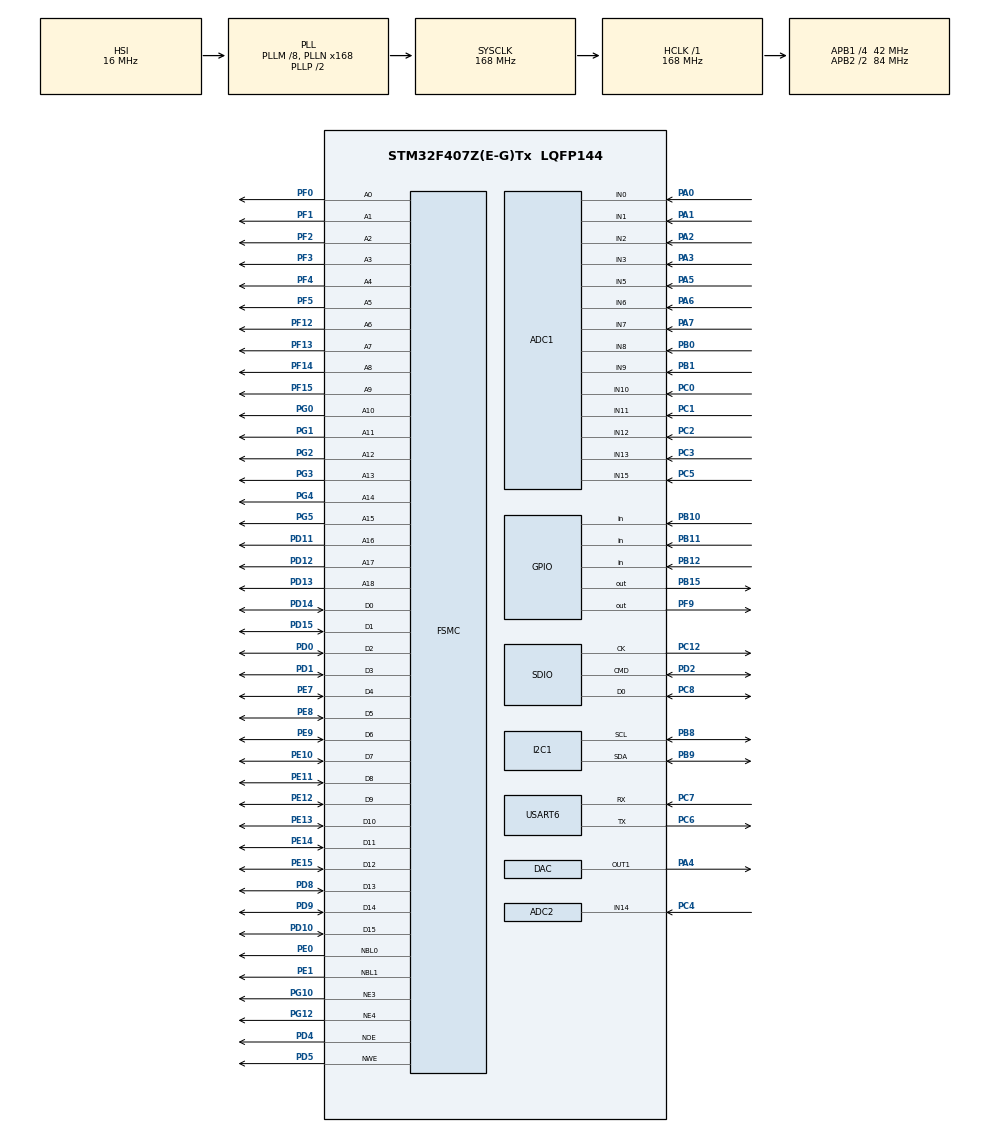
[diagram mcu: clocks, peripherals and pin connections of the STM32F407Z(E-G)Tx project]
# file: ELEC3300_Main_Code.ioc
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ADC1.Channel-0\#ChannelRegularConversion=ADC_CHANNEL_0
ADC1.Channel-1\#ChannelRegularConversion=ADC_CHANNEL_1
ADC1.Channel-10\#ChannelRegularConversion=ADC_CHANNEL_11
ADC1.Channel-11\#ChannelRegularConversion=ADC_CHANNEL_12
ADC1.Channel-12\#ChannelRegularConversion=ADC_CHANNEL_13
ADC1.Channel-13\#ChannelRegularConversion=ADC_CHANNEL_15
ADC1.Channel-2\#ChannelRegularConversion=ADC_CHANNEL_2
ADC1.Channel-3\#ChannelRegularConversion=ADC_CHANNEL_3
ADC1.Channel-4\#ChannelRegularConversion=ADC_CHANNEL_5
ADC1.Channel-5\#ChannelRegularConversion=ADC_CHANNEL_6
ADC1.Channel-6\#ChannelRegularConversion=ADC_CHANNEL_7
ADC1.Channel-7\#ChannelRegularConversion=ADC_CHANNEL_8
ADC1.Channel-8\#ChannelRegularConversion=ADC_CHANNEL_9
ADC1.Channel-9\#ChannelRegularConversion=ADC_CHANNEL_10
ADC1.ClockPrescaler=ADC_CLOCK_SYNC_PCLK_DIV4
ADC1.ContinuousConvMode=ENABLE
ADC1.DMAContinuousRequests=ENABLE
ADC1.NbrOfConversion=14
ADC1.NbrOfConversionFlag=1
ADC1.Rank-0\#ChannelRegularConversion=1
ADC1.Rank-1\#ChannelRegularConversion=2
ADC1.Rank-10\#ChannelRegularConversion=11
ADC1.Rank-11\#ChannelRegularConversion=12
ADC1.Rank-12\#ChannelRegularConversion=13
ADC1.Rank-13\#ChannelRegularConversion=14
ADC1.Rank-2\#ChannelRegularConversion=3
ADC1.Rank-3\#ChannelRegularConversion=4
ADC1.Rank-4\#ChannelRegularConversion=5
ADC1.Rank-5\#ChannelRegularConversion=6
ADC1.Rank-6\#ChannelRegularConversion=7
ADC1.Rank-7\#ChannelRegularConversion=8
ADC1.Rank-8\#ChannelRegularConversion=9
ADC1.Rank-9\#ChannelRegularConversion=10
ADC1.SamplingTime-0\#ChannelRegularConversion=ADC_SAMPLETIME_56CYCLES
ADC1.SamplingTime-1\#ChannelRegularConversion=ADC_SAMPLETIME_56CYCLES
ADC1.SamplingTime-10\#ChannelRegularConversion=ADC_SAMPLETIME_56CYCLES
ADC1.SamplingTime-11\#ChannelRegularConversion=ADC_SAMPLETIME_56CYCLES
ADC1.SamplingTime-12\#ChannelRegularConversion=ADC_SAMPLETIME_56CYCLES
ADC1.SamplingTime-13\#ChannelRegularConversion=ADC_SAMPLETIME_56CYCLES
ADC1.SamplingTime-2\#ChannelRegularConversion=ADC_SAMPLETIME_56CYCLES
ADC1.SamplingTime-3\#ChannelRegularConversion=ADC_SAMPLETIME_56CYCLES
ADC1.SamplingTime-4\#ChannelRegularConversion=ADC_SAMPLETIME_56CYCLES
ADC1.SamplingTime-5\#ChannelRegularConversion=ADC_SAMPLETIME_56CYCLES
ADC1.SamplingTime-6\#ChannelRegularConversion=ADC_SAMPLETIME_56CYCLES
ADC1.SamplingTime-7\#ChannelRegularConversion=ADC_SAMPLETIME_56CYCLES
ADC1.SamplingTime-8\#ChannelRegularConversion=ADC_SAMPLETIME_56CYCLES
ADC1.SamplingTime-9\#ChannelRegularConversion=ADC_SAMPLETIME_56CYCLES
ADC1.master=1
ADC2.Channel-0\#ChannelRegularConversion=ADC_CHANNEL_14
ADC2.ClockPrescaler=ADC_CLOCK_SYNC_PCLK_DIV4
ADC2.ContinuousConvMode=ENABLE
ADC2.DMAContinuousRequests=ENABLE
ADC2.NbrOfConversionFlag=1
ADC2.Rank-0\#ChannelRegularConversion=1
ADC2.SamplingTime-0\#ChannelRegularConversion=ADC_SAMPLETIME_3CYCLES
DAC.DAC_Trigger=DAC_TRIGGER_T4_TRGO
Dma.ADC1.4.Direction=DMA_PERIPH_TO_MEMORY
Dma.ADC1.4.FIFOMode=DMA_FIFOMODE_DISABLE
Dma.ADC1.4.Instance=DMA2_Stream4
Dma.ADC1.4.MemDataAlignment=DMA_MDATAALIGN_HALFWORD
Dma.ADC1.4.MemInc=DMA_MINC_ENABLE
Dma.ADC1.4.Mode=DMA_CIRCULAR
Dma.ADC1.4.PeriphDataAlignment=DMA_PDATAALIGN_HALFWORD
Dma.ADC1.4.PeriphInc=DMA_PINC_DISABLE
Dma.ADC1.4.Priority=DMA_PRIORITY_LOW
Dma.ADC2.2.Direction=DMA_PERIPH_TO_MEMORY
Dma.ADC2.2.FIFOMode=DMA_FIFOMODE_DISABLE
Dma.ADC2.2.Instance=DMA2_Stream2
Dma.ADC2.2.MemDataAlignment=DMA_MDATAALIGN_HALFWORD
Dma.ADC2.2.MemInc=DMA_MINC_ENABLE
Dma.ADC2.2.Mode=DMA_NORMAL
Dma.ADC2.2.PeriphDataAlignment=DMA_PDATAALIGN_HALFWORD
Dma.ADC2.2.PeriphInc=DMA_PINC_DISABLE
Dma.ADC2.2.Priority=DMA_PRIORITY_LOW
Dma.DAC1.3.Direction=DMA_MEMORY_TO_PERIPH
Dma.DAC1.3.FIFOMode=DMA_FIFOMODE_DISABLE
Dma.DAC1.3.Instance=DMA1_Stream5
Dma.DAC1.3.MemDataAlignment=DMA_MDATAALIGN_HALFWORD
Dma.DAC1.3.MemInc=DMA_MINC_ENABLE
Dma.DAC1.3.Mode=DMA_NORMAL
Dma.DAC1.3.PeriphDataAlignment=DMA_PDATAALIGN_HALFWORD
Dma.DAC1.3.PeriphInc=DMA_PINC_DISABLE
Dma.DAC1.3.Priority=DMA_PRIORITY_VERY_HIGH
Dma.MEMTOMEM.5.Direction=DMA_MEMORY_TO_MEMORY
Dma.MEMTOMEM.5.FIFOMode=DMA_FIFOMODE_ENABLE
Dma.MEMTOMEM.5.FIFOThreshold=DMA_FIFO_THRESHOLD_FULL
Dma.MEMTOMEM.5.Instance=DMA2_Stream1
Dma.MEMTOMEM.5.MemBurst=DMA_MBURST_SINGLE
Dma.MEMTOMEM.5.MemDataAlignment=DMA_MDATAALIGN_HALFWORD
Dma.MEMTOMEM.5.MemInc=DMA_MINC_ENABLE
Dma.MEMTOMEM.5.Mode=DMA_NORMAL
Dma.MEMTOMEM.5.PeriphBurst=DMA_PBURST_SINGLE
Dma.MEMTOMEM.5.PeriphDataAlignment=DMA_PDATAALIGN_HALFWORD
Dma.MEMTOMEM.5.PeriphInc=DMA_PINC_ENABLE
Dma.MEMTOMEM.5.Priority=DMA_PRIORITY_HIGH
Dma.Request0=SDIO_RX
Dma.Request1=SDIO_TX
Dma.Request2=ADC2
Dma.Request3=DAC1
Dma.Request4=ADC1
Dma.Request5=MEMTOMEM
Dma.SDIO_RX.0.Direction=DMA_PERIPH_TO_MEMORY
Dma.SDIO_RX.0.FIFOMode=DMA_FIFOMODE_ENABLE
Dma.SDIO_RX.0.FIFOThreshold=DMA_FIFO_THRESHOLD_FULL
Dma.SDIO_RX.0.Instance=DMA2_Stream6
Dma.SDIO_RX.0.MemBurst=DMA_MBURST_INC4
Dma.SDIO_RX.0.MemDataAlignment=DMA_MDATAALIGN_WORD
Dma.SDIO_RX.0.MemInc=DMA_MINC_ENABLE
Dma.SDIO_RX.0.Mode=DMA_PFCTRL
Dma.SDIO_RX.0.PeriphBurst=DMA_PBURST_INC4
Dma.SDIO_RX.0.PeriphDataAlignment=DMA_PDATAALIGN_WORD
Dma.SDIO_RX.0.PeriphInc=DMA_PINC_DISABLE
Dma.SDIO_RX.0.Priority=DMA_PRIORITY_LOW
Dma.SDIO_TX.1.Direction=DMA_MEMORY_TO_PERIPH
Dma.SDIO_TX.1.FIFOMode=DMA_FIFOMODE_ENABLE
Dma.SDIO_TX.1.FIFOThreshold=DMA_FIFO_THRESHOLD_FULL
Dma.SDIO_TX.1.Instance=DMA2_Stream3
Dma.SDIO_TX.1.MemBurst=DMA_MBURST_INC4
Dma.SDIO_TX.1.MemDataAlignment=DMA_MDATAALIGN_WORD
Dma.SDIO_TX.1.MemInc=DMA_MINC_ENABLE
Dma.SDIO_TX.1.Mode=DMA_PFCTRL
Dma.SDIO_TX.1.PeriphBurst=DMA_PBURST_INC4
Dma.SDIO_TX.1.PeriphDataAlignment=DMA_PDATAALIGN_WORD
Dma.SDIO_TX.1.PeriphInc=DMA_PINC_DISABLE
Dma.SDIO_TX.1.Priority=DMA_PRIORITY_LOW
FATFS._FS_EXFAT=0
FATFS._MAX_SS=4096
FATFS._USE_LFN=1
FSMC.AddressSetupTime1=1
FSMC.AddressSetupTime2=0
FSMC.BusTurnAroundDuration1=0
FSMC.BusTurnAroundDuration2=0
FSMC.DataSetupTime1=5
FSMC.DataSetupTime2=8
FSMC.WriteOperation2=FSMC_WRITE_OPERATION_ENABLE
I2C1.I2C_Mode=I2C_Fast
Mcu.Family=STM32F4
Mcu.Name=STM32F407Z(E-G)Tx
Mcu.Package=LQFP144
NVIC.ADC_IRQn=true\:0\:0\:false\:false\:true\:true\:true\:true
NVIC.DMA1_Stream5_IRQn=true\:0\:0\:false\:false\:true\:false\:true\:true
NVIC.DMA2_Stream2_IRQn=true\:0\:0\:false\:false\:true\:false\:true\:true
NVIC.DMA2_Stream3_IRQn=true\:0\:0\:false\:false\:true\:false\:true\:true
NVIC.DMA2_Stream4_IRQn=true\:0\:0\:false\:false\:true\:false\:true\:true
NVIC.DMA2_Stream6_IRQn=true\:0\:0\:false\:false\:true\:false\:true\:true
NVIC.PriorityGroup=NVIC_PRIORITYGROUP_4
PA0-WKUP.Signal=ADCx_IN0
PA1.Signal=ADCx_IN1
PA13.Mode=JTAG_4_pins
PA13.Signal=SYS_JTMS-SWDIO
PA14.Mode=JTAG_4_pins
PA14.Signal=SYS_JTCK-SWCLK
PA15.Mode=JTAG_4_pins
PA15.Signal=SYS_JTDI
PA2.Signal=ADCx_IN2
PA3.Signal=ADCx_IN3
PA4.Signal=COMP_DAC1_group
PA5.Signal=ADCx_IN5
PA6.Signal=ADCx_IN6
PA7.Signal=ADCx_IN7
PB0.Signal=ADCx_IN8
PB1.Signal=ADCx_IN9
PB10.GPIO_PuPd=GPIO_PULLDOWN
PB10.Signal=GPIO_Input
PB11.GPIO_PuPd=GPIO_PULLDOWN
PB11.Signal=GPIO_Input
PB12.Signal=GPIO_Input
PB15.Signal=GPIO_Output
PB3.Mode=JTAG_4_pins
PB3.Signal=SYS_JTDO-SWO
PB8.Mode=I2C
PB8.Signal=I2C1_SCL
PB9.Mode=I2C
PB9.Signal=I2C1_SDA
PC0.Signal=ADCx_IN10
PC1.Signal=ADCx_IN11
PC12.Mode=SD_1_bit
PC12.Signal=SDIO_CK
PC2.Signal=ADCx_IN12
PC3.Signal=ADCx_IN13
PC4.Signal=ADCx_IN14
PC5.Signal=ADCx_IN15
PC6.Mode=Asynchronous
PC6.Signal=USART6_TX
PC7.Mode=Asynchronous
PC7.Signal=USART6_RX
PC8.Mode=SD_1_bit
PC8.Signal=SDIO_D0
PD0.Signal=FSMC_D2_DA2
PD1.Signal=FSMC_D3_DA3
PD10.Signal=FSMC_D15_DA15
PD11.Signal=FSMC_A16_CLE
PD12.Signal=FSMC_A17_ALE
PD13.Signal=FSMC_A18
PD14.Signal=FSMC_D0_DA0
PD15.Signal=FSMC_D1_DA1
PD2.Mode=SD_1_bit
PD2.Signal=SDIO_CMD
PD4.Signal=FSMC_NOE
PD5.Signal=FSMC_NWE
PD8.Signal=FSMC_D13_DA13
PD9.Signal=FSMC_D14_DA14
PE0.Signal=FSMC_NBL0
PE1.Signal=FSMC_NBL1
PE10.Signal=FSMC_D7_DA7
PE11.Signal=FSMC_D8_DA8
PE12.Signal=FSMC_D9_DA9
PE13.Signal=FSMC_D10_DA10
PE14.Signal=FSMC_D11_DA11
PE15.Signal=FSMC_D12_DA12
PE7.Signal=FSMC_D4_DA4
PE8.Signal=FSMC_D5_DA5
PE9.Signal=FSMC_D6_DA6
PF0.Signal=FSMC_A0
PF1.Signal=FSMC_A1
PF12.Signal=FSMC_A6
PF13.Signal=FSMC_A7
PF14.Signal=FSMC_A8
PF15.Signal=FSMC_A9
PF2.Signal=FSMC_A2
PF3.Signal=FSMC_A3
PF4.Signal=FSMC_A4
PF5.Signal=FSMC_A5
PF9.Signal=GPIO_Output
PG0.Signal=FSMC_A10
PG1.Signal=FSMC_A11
PG10.Mode=NorPsramChipSelect3_2
PG10.Signal=FSMC_NE3
PG12.Mode=NorPsramChipSelect4_1
PG12.Signal=FSMC_NE4
PG2.Signal=FSMC_A12
PG3.Signal=FSMC_A13
PG4.Signal=FSMC_A14
PG5.Signal=FSMC_A15
PH0-OSC_IN.Mode=HSE-External-Oscillator
PH0-OSC_IN.Signal=RCC_OSC_IN
PH1-OSC_OUT.Mode=HSE-External-Oscillator
PH1-OSC_OUT.Signal=RCC_OSC_OUT
ProjectManager.HeapSize=0x200
ProjectManager.StackSize=0x400
ProjectManager.TargetToolchain=STM32CubeIDE
RCC.48MHZClocksFreq_Value=48000000
RCC.AHBFreq_Value=168000000
RCC.APB1CLKDivider=RCC_HCLK_DIV4
RCC.APB1Freq_Value=42000000
RCC.APB1TimFreq_Value=84000000
RCC.APB2CLKDivider=RCC_HCLK_DIV2
RCC.APB2Freq_Value=84000000
RCC.APB2TimFreq_Value=168000000
RCC.CortexFreq_Value=168000000
RCC.HCLKFreq_Value=168000000
RCC.HSE_VALUE=8000000
RCC.HSI_VALUE=16000000
RCC.LSE_VALUE=32768
RCC.PLLM=8
RCC.PLLN=168
RCC.PLLQ=7
RCC.SYSCLKFreq_VALUE=168000000
RCC.SYSCLKSource=RCC_SYSCLKSOURCE_PLLCLK
RCC.VCOOutputFreq_Value=336000000
RTC.Date=5
RTC.Hours=12
RTC.Minutes=40
RTC.Month=RTC_MONTH_APRIL
RTC.WeekDay=RTC_WEEKDAY_SUNDAY
RTC.Year=25
SDIO.ClockDiv=12
SH.ADCx_IN0.0=ADC1_IN0,IN0
SH.ADCx_IN1.0=ADC1_IN1,IN1
SH.ADCx_IN10.0=ADC1_IN10,IN10
SH.ADCx_IN11.0=ADC1_IN11,IN11
SH.ADCx_IN12.0=ADC1_IN12,IN12
SH.ADCx_IN13.0=ADC1_IN13,IN13
SH.ADCx_IN14.0=ADC2_IN14,IN14
SH.ADCx_IN15.0=ADC1_IN15,IN15
SH.ADCx_IN2.0=ADC1_IN2,IN2
SH.ADCx_IN3.0=ADC1_IN3,IN3
SH.ADCx_IN5.0=ADC1_IN5,IN5
SH.ADCx_IN6.0=ADC1_IN6,IN6
SH.ADCx_IN7.0=ADC1_IN7,IN7
SH.ADCx_IN8.0=ADC1_IN8,IN8
SH.ADCx_IN9.0=ADC1_IN9,IN9
SH.COMP_DAC1_group.0=DAC_OUT1,DAC_OUT1
SH.FSMC_A0.0=FSMC_A0,19b-a2
SH.FSMC_A1.0=FSMC_A1,19b-a2
SH.FSMC_A10.0=FSMC_A10,19b-a2
SH.FSMC_A11.0=FSMC_A11,19b-a2
SH.FSMC_A12.0=FSMC_A12,19b-a2
SH.FSMC_A13.0=FSMC_A13,19b-a2
SH.FSMC_A14.0=FSMC_A14,19b-a2
SH.FSMC_A15.0=FSMC_A15,19b-a2
SH.FSMC_A16_CLE.0=FSMC_A16,19b-a2
SH.FSMC_A17_ALE.0=FSMC_A17,19b-a2
SH.FSMC_A18.0=FSMC_A18,19b-a2
SH.FSMC_A2.0=FSMC_A2,19b-a2
SH.FSMC_A3.0=FSMC_A3,19b-a2
SH.FSMC_A4.0=FSMC_A4,19b-a2
SH.FSMC_A5.0=FSMC_A5,19b-a2
SH.FSMC_A6.0=FSMC_A6,A6_1
SH.FSMC_A6.1=FSMC_A6,19b-a2
SH.FSMC_A7.0=FSMC_A7,19b-a2
SH.FSMC_A8.0=FSMC_A8,19b-a2
SH.FSMC_A9.0=FSMC_A9,19b-a2
SH.FSMC_D0_DA0.0=FSMC_D0,16b-d1
SH.FSMC_D0_DA0.1=FSMC_D0,16b-d2
SH.FSMC_D10_DA10.0=FSMC_D10,16b-d1
SH.FSMC_D10_DA10.1=FSMC_D10,16b-d2
SH.FSMC_D11_DA11.0=FSMC_D11,16b-d1
SH.FSMC_D11_DA11.1=FSMC_D11,16b-d2
SH.FSMC_D12_DA12.0=FSMC_D12,16b-d1
SH.FSMC_D12_DA12.1=FSMC_D12,16b-d2
SH.FSMC_D13_DA13.0=FSMC_D13,16b-d1
SH.FSMC_D13_DA13.1=FSMC_D13,16b-d2
SH.FSMC_D14_DA14.0=FSMC_D14,16b-d1
SH.FSMC_D14_DA14.1=FSMC_D14,16b-d2
SH.FSMC_D15_DA15.0=FSMC_D15,16b-d1
SH.FSMC_D15_DA15.1=FSMC_D15,16b-d2
SH.FSMC_D1_DA1.0=FSMC_D1,16b-d1
SH.FSMC_D1_DA1.1=FSMC_D1,16b-d2
SH.FSMC_D2_DA2.0=FSMC_D2,16b-d1
SH.FSMC_D2_DA2.1=FSMC_D2,16b-d2
SH.FSMC_D3_DA3.0=FSMC_D3,16b-d1
SH.FSMC_D3_DA3.1=FSMC_D3,16b-d2
SH.FSMC_D4_DA4.0=FSMC_D4,16b-d1
SH.FSMC_D4_DA4.1=FSMC_D4,16b-d2
SH.FSMC_D5_DA5.0=FSMC_D5,16b-d1
SH.FSMC_D5_DA5.1=FSMC_D5,16b-d2
SH.FSMC_D6_DA6.0=FSMC_D6,16b-d1
SH.FSMC_D6_DA6.1=FSMC_D6,16b-d2
SH.FSMC_D7_DA7.0=FSMC_D7,16b-d1
SH.FSMC_D7_DA7.1=FSMC_D7,16b-d2
SH.FSMC_D8_DA8.0=FSMC_D8,16b-d1
SH.FSMC_D8_DA8.1=FSMC_D8,16b-d2
SH.FSMC_D9_DA9.0=FSMC_D9,16b-d1
SH.FSMC_D9_DA9.1=FSMC_D9,16b-d2
SH.FSMC_NBL0.0=FSMC_NBL0,2ByteEnable2
SH.FSMC_NBL1.0=FSMC_NBL1,2ByteEnable2
SH.FSMC_NOE.0=FSMC_NOE,Lcd1
SH.FSMC_NOE.1=FSMC_NOE,Sram2
SH.FSMC_NWE.0=FSMC_NWE,Lcd1
SH.FSMC_NWE.1=FSMC_NWE,Sram2
TIM4.Period=4
TIM4.Prescaler=1679
TIM4.TIM_MasterOutputTrigger=TIM_TRGO_UPDATE
USART6.VirtualMode=VM_ASYNC
VP_FATFS_VS_SDIO.Mode=SDIO
VP_RTC_VS_RTC_Activate.Mode=RTC_Enabled
VP_RTC_VS_RTC_Calendar.Mode=RTC_Calendar
VP_TIM4_VS_ClockSourceINT.Mode=Internal
board=custom

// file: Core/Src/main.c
/* USER CODE BEGIN Header */
/**
  ******************************************************************************
  * @file           : main.c
  * @brief          : Main program body
  ******************************************************************************
  * @attention
  *
  * Copyright (c) 2025 STMicroelectronics.
  * All rights reserved.
  *
  * This software is licensed under terms that can be found in the LICENSE file
  * in the root directory of this software component.
  * If no LICENSE file comes with this software, it is provided AS-IS.
  *
  ******************************************************************************
  */
/* USER CODE END Header */
#include "main.h"
#include "fatfs.h"

/* USER CODE BEGIN Includes */
//#include "state_controller.h"

#include "soundtracks.h"
#include "bitmaps.h"

#include "SDcard.h"
#include "lcd.h"
#include "VL53L0X.h"
#include "MPU6050.h"

#include "Audio_Player.h"
#include "servo_adc_read.h"
#include "pid.h"
#include "servo_pid_set.h"
#include "inverse_kinematics.h"
#include "interaction_timer.h"
#include "uart_receiver.h"
#include "watchdog_function.h"

#include "movement_controller.h"
#include "face_controller.h"
#include "state_controller.h"

/* USER CODE END Includes */

ADC_HandleTypeDef hadc1;
ADC_HandleTypeDef hadc2;
DMA_HandleTypeDef hdma_adc1;
DMA_HandleTypeDef hdma_adc2;

DAC_HandleTypeDef hdac;
DMA_HandleTypeDef hdma_dac1;

I2C_HandleTypeDef hi2c1;

RTC_HandleTypeDef hrtc;

SD_HandleTypeDef hsd;
DMA_HandleTypeDef hdma_sdio_rx;
DMA_HandleTypeDef hdma_sdio_tx;

TIM_HandleTypeDef htim4;

UART_HandleTypeDef huart6;

DMA_HandleTypeDef hdma_memtomem_dma2_stream1;
SRAM_HandleTypeDef hsram1;
SRAM_HandleTypeDef hsram2;

void SystemClock_Config(void);
static void MX_GPIO_Init(void);
static void MX_DMA_Init(void);
static void MX_FSMC_Init(void);
static void MX_SDIO_SD_Init(void);
static void MX_ADC2_Init(void);
static void MX_ADC1_Init(void);
static void MX_DAC_Init(void);
static void MX_TIM4_Init(void);
static void MX_I2C1_Init(void);
static void MX_RTC_Init(void);
static void MX_USART6_UART_Init(void);

/* USER CODE BEGIN 0 */

// FLAT is 100, 0, 0
float acc_x, acc_y, acc_z;

int distance;
/* USER CODE END 0 */

int main(void)
{
  /* USER CODE BEGIN 1 */
  int sys_tick_c = 0, sys_tick_p_1 = 0, sys_tick_p_100 = 0, sys_tick_p_move = 0;
  int walk_state = 0;

//  double femur_trajectory_walk[] = {55, 55, 90, 44};
//  double tibia_trajectory_walk[] = {118, 137, 137, 99};
  double femur_trajectory_walk[4] = {60, 45, 102, 51};
  double tibia_trajectory_walk[4] = {115, 128, 135, 106};

//  double LB_FEMUR_setpoints[bufLen] = {0};
//  double LB_TIBIA_setpoints[bufLen] = {0};
  /* USER CODE END 1 */

  /* MCU Configuration--------------------------------------------------------*/

  /* Reset of all peripherals, Initializes the Flash interface and the Systick. */
  HAL_Init();

  /* Configure the system clock */
  SystemClock_Config();

  /* Initialize all configured peripherals */
  MX_GPIO_Init();
  MX_DMA_Init();
  MX_FSMC_Init();
  MX_SDIO_SD_Init();
  MX_FATFS_Init();
  MX_ADC2_Init();
  MX_ADC1_Init();
  MX_DAC_Init();
  MX_TIM4_Init();
  MX_I2C1_Init();
  MX_RTC_Init();
  MX_USART6_UART_Init();
  /* USER CODE BEGIN 2 */

	// Configuring systick
	HAL_SetTickFreq(HAL_TICK_FREQ_1KHZ);

	// Initalizing the LCD
	LCD_INIT();
	LCD_BackLed_Control(DISABLE);

	// Mounting SD cards
	LCD_DrawString(0, 0, "INIT SD");
	SDcard_STATUS status = SD_Init();
	if (status != SDcard_OK) {
	  HardFault_Handler();
	}
	LCD_DrawString(150, 0, "SD OK");

	// Initializing the MPU6050
	MPU6050_init();
	MPU6050_Read_Accel(&acc_x, &acc_y, &acc_z);

//	 Initalizing the VL53L0X
	statInfo_t_VL53L0X distanceStr;
	initVL53L0X(1, &hi2c1);

	// Configure the sensor for high accuracy and speed in 20 cm.
	setSignalRateLimit(2);
	setVcselPulsePeriod(VcselPeriodPreRange, 10);
	setVcselPulsePeriod(VcselPeriodFinalRange, 14);
	setMeasurementTimingBudget(300 * 1000UL);

	// Initializing the servo angle reading
	servoAngleReader servo_reader;
	servo_reader.servoADC = &hadc1;
	servoReaderStart(&servo_reader);

	// Initalizing the servo pid
	servo_set servoSet;

	// Check out these retarded declarations
	PID_TypeDef LB_Tibia_PID;
	PID_TypeDef LB_Femur_PID;
	PID_TypeDef LB_Shoul_PID;
	PID_TypeDef LF_Tibia_PID;
	PID_TypeDef LF_Femur_PID;
	PID_TypeDef LF_Shoul_PID;
	PID_TypeDef RF_Tibia_PID;
	PID_TypeDef RF_Femur_PID;
	PID_TypeDef RF_Shoul_PID;
	PID_TypeDef RB_Tibia_PID;
	PID_TypeDef RB_Femur_PID;
	PID_TypeDef RB_Shoul_PID;

	// Instantiating the PCA PWM controllers
	static pca9685_handle_t GPWM_1;
	static pca9685_handle_t GPWM_2;

	GPWM_1.device_address = 0x61 << 1;
	GPWM_2.device_address = 0x60 << 1;

	GPWM_1.i2c_handle = &hi2c1;
	GPWM_2.i2c_handle = &hi2c1;

	GPWM_1.inverted = 0;
	GPWM_2.inverted = 0;

	servoSet.pwm_out_1 = &GPWM_1;
	servoSet.pwm_out_2 = &GPWM_2;

	servoSet.LB_Tibia_PID = &LB_Tibia_PID;
	servoSet.LB_Femur_PID = &LB_Femur_PID;
	servoSet.LB_Shoul_PID = &LB_Shoul_PID;
	servoSet.LF_Tibia_PID = &LF_Tibia_PID;
	servoSet.LF_Femur_PID = &LF_Femur_PID;
	servoSet.LF_Shoul_PID = &LF_Shoul_PID;
	servoSet.RF_Tibia_PID = &RF_Tibia_PID;
	servoSet.RF_Femur_PID = &RF_Femur_PID;
	servoSet.RF_Shoul_PID = &RF_Shoul_PID;
	servoSet.RB_Tibia_PID = &RB_Tibia_PID;
	servoSet.RB_Femur_PID = &RB_Femur_PID;
	servoSet.RB_Shoul_PID = &RB_Shoul_PID;

	// Initalizing the PCA9685
	LCD_DrawString(0, 20, "INIT PCA9685");
	if (!pidInit(&servoSet)) {
		LCD_DrawString(150, 20, "FAIL");
		HardFault_Handler();
	}
	LCD_DrawString(150, 20, "PCA9685 OK");

	// Initalizing the inverse kinematic objects
	leg_position LB_pos;
	leg_position RB_pos;
	leg_position LF_pos;
	leg_position RF_pos;

	LB_pos.leg = LB;
	RB_pos.leg = RB;
	LF_pos.leg = LF;
	RF_pos.leg = RF;

	// Initializing the audio player
	audioController AudioCtrl;

	AudioCtrl.hdac = &hdac;
	AudioCtrl.htim = &htim4;
	AudioCtrl.dac_channel = DAC_CHANNEL_1;

	LCD_DrawString(0, 40, "LOADING AUDIO FILE");
	initAudio(&AudioCtrl);
	loadAudioFiles();

	// Initalizing the interaction timer
	interaction_timer interactionTimer;
	interactionTimer.hrtc = &hrtc;
	interactionTimer.sadThresholdDay = SAD_THRESHOLD_DAY;
	interactionTimer.sadThresholdHour = SAD_THRESHOLD_HOUR;
	interactionTimer.sadThresholdMin = SAD_THRESHOLD_MIN;
	interactUpdate(&interactionTimer);

	// Initializing the face controller
	face_controller faceController;
	faceController.animation_counter = 0;

  movement_controller moveController;
  moveController.movement_counter = 0;
  moveController.executing_state = STANDING;

	// Initializing the state controller
	state_controller stateController;
	stateController._servo_reader = &servo_reader;
	stateController.interactionTimer = &interactionTimer;
	stateController._audio_controller = &AudioCtrl;
	stateController.current_mm_state = NORMAL;
	stateController.current_move_state = STANDING;
	stateController.bt_uart = &huart6;
	stateController.distanceStr = &distanceStr;
  /* USER CODE END 2 */

  /* Infinite loop */
  while (1)
  {

    /* USER CODE BEGIN 3 */
	  sys_tick_c = HAL_GetTick();

//	  MPU6050_Read_Accel(&acc_x, &acc_y, &acc_z);
//	  distance = readRangeSingleMillimeters(&distanceStr);

	  // 1 Hz Processes
	  if ((sys_tick_c - sys_tick_p_1) >= 1000) {
		  sys_tick_p_1 = sys_tick_c;
		  HAL_GPIO_TogglePin(GPIOF, GPIO_PIN_9);
		  HAL_StatusTypeDef remote_status = receive_normal_data(stateController.bt_uart, &stateController.joystick_x, &stateController.joystick_y, &stateController.joystick_button, &stateController.ts_button);
		  updateFace(&faceController, &stateController);
	  }

    //  Hz Processes
	  if ((sys_tick_c - sys_tick_p_move) >= 10) {
		  sys_tick_p_move = sys_tick_c;
		  updateMovements(&moveController, &stateController, &servoSet, &LB_pos, &RB_pos, &LF_pos, &RF_pos);
	  }

	  // 1000 Hz Processes
	  if ((sys_tick_c - sys_tick_p_100) >= 1) {
		  sys_tick_p_100 = sys_tick_c;

//		  setDesiredPosition(&LB_pos, X_OFFSET, Y_OFFSET, 3.9);
//		  setDesiredPosition(&RB_pos, X_OFFSET, Y_OFFSET, 3.9);
//		  setDesiredPosition(&LF_pos, X_OFFSET, Y_OFFSET, 3.9);
//		  setDesiredPosition(&RF_pos, X_OFFSET, Y_OFFSET, 3.9);
//
//		  updateLeg(&LB_pos, &servoSet);
//		  updateLeg(&RB_pos, &servoSet);
//		  updateLeg(&LF_pos, &servoSet);
//		  updateLeg(&RF_pos, &servoSet);

		  // Begin the process
		  determineMultimediaState(&stateController);
	      determineMovementState(&stateController);

	      updateLeg(&LB_pos, &servoSet);
		  updateLeg(&RB_pos, &servoSet);
	      updateLeg(&LF_pos, &servoSet);
	      updateLeg(&RF_pos, &servoSet);
	  }

	updateAngles(&servo_reader);
	updateAnglesArray(&servoSet, servo_reader.servoAngles);
	updateServo(&servoSet); // Poll every time!

  }
  /* USER CODE END 3 */
}

void SystemClock_Config(void)
{
  RCC_OscInitTypeDef RCC_OscInitStruct = {0};
  RCC_ClkInitTypeDef RCC_ClkInitStruct = {0};

  /** Configure the main internal regulator output voltage
  */
  __HAL_RCC_PWR_CLK_ENABLE();
  __HAL_PWR_VOLTAGESCALING_CONFIG(PWR_REGULATOR_VOLTAGE_SCALE1);

  /** Initializes the RCC Oscillators according to the specified parameters
  * in the RCC_OscInitTypeDef structure.
  */
  RCC_OscInitStruct.OscillatorType = RCC_OSCILLATORTYPE_HSI|RCC_OSCILLATORTYPE_LSI;
  RCC_OscInitStruct.HSIState = RCC_HSI_ON;
  RCC_OscInitStruct.HSICalibrationValue = RCC_HSICALIBRATION_DEFAULT;
  RCC_OscInitStruct.LSIState = RCC_LSI_ON;
  RCC_OscInitStruct.PLL.PLLState = RCC_PLL_ON;
  RCC_OscInitStruct.PLL.PLLSource = RCC_PLLSOURCE_HSI;
  RCC_OscInitStruct.PLL.PLLM = 8;
  RCC_OscInitStruct.PLL.PLLN = 168;
  RCC_OscInitStruct.PLL.PLLP = RCC_PLLP_DIV2;
  RCC_OscInitStruct.PLL.PLLQ = 7;
  if (HAL_RCC_OscConfig(&RCC_OscInitStruct) != HAL_OK)
  {
    Error_Handler();
  }

  /** Initializes the CPU, AHB and APB buses clocks
  */
  RCC_ClkInitStruct.ClockType = RCC_CLOCKTYPE_HCLK|RCC_CLOCKTYPE_SYSCLK
                              |RCC_CLOCKTYPE_PCLK1|RCC_CLOCKTYPE_PCLK2;
  RCC_ClkInitStruct.SYSCLKSource = RCC_SYSCLKSOURCE_PLLCLK;
  RCC_ClkInitStruct.AHBCLKDivider = RCC_SYSCLK_DIV1;
  RCC_ClkInitStruct.APB1CLKDivider = RCC_HCLK_DIV4;
  RCC_ClkInitStruct.APB2CLKDivider = RCC_HCLK_DIV2;

  if (HAL_RCC_ClockConfig(&RCC_ClkInitStruct, FLASH_LATENCY_5) != HAL_OK)
  {
    Error_Handler();
  }
}

static void MX_ADC1_Init(void)
{

  ADC_ChannelConfTypeDef sConfig = {0};

  /** Configure the global features of the ADC (Clock, Resolution, Data Alignment and number of conversion)
  */
  hadc1.Instance = ADC1;
  hadc1.Init.ClockPrescaler = ADC_CLOCK_SYNC_PCLK_DIV4;
  hadc1.Init.Resolution = ADC_RESOLUTION_12B;
  hadc1.Init.ScanConvMode = ENABLE;
  hadc1.Init.ContinuousConvMode = ENABLE;
  hadc1.Init.DiscontinuousConvMode = DISABLE;
  hadc1.Init.ExternalTrigConvEdge = ADC_EXTERNALTRIGCONVEDGE_NONE;
  hadc1.Init.ExternalTrigConv = ADC_SOFTWARE_START;
  hadc1.Init.DataAlign = ADC_DATAALIGN_RIGHT;
  hadc1.Init.NbrOfConversion = 14;
  hadc1.Init.DMAContinuousRequests = ENABLE;
  hadc1.Init.EOCSelection = ADC_EOC_SINGLE_CONV;
  if (HAL_ADC_Init(&hadc1) != HAL_OK)
  {
    Error_Handler();
  }

  /** Configure for the selected ADC regular channel its corresponding rank in the sequencer and its sample time.
  */
  sConfig.Channel = ADC_CHANNEL_0;
  sConfig.Rank = 1;
  sConfig.SamplingTime = ADC_SAMPLETIME_56CYCLES;
  if (HAL_ADC_ConfigChannel(&hadc1, &sConfig) != HAL_OK)
  {
    Error_Handler();
  }

  /** Configure for the selected ADC regular channel its corresponding rank in the sequencer and its sample time.
  */
  sConfig.Channel = ADC_CHANNEL_1;
  sConfig.Rank = 2;
  if (HAL_ADC_ConfigChannel(&hadc1, &sConfig) != HAL_OK)
  {
    Error_Handler();
  }

  /** Configure for the selected ADC regular channel its corresponding rank in the sequencer and its sample time.
  */
  sConfig.Channel = ADC_CHANNEL_2;
  sConfig.Rank = 3;
  if (HAL_ADC_ConfigChannel(&hadc1, &sConfig) != HAL_OK)
  {
    Error_Handler();
  }

  /** Configure for the selected ADC regular channel its corresponding rank in the sequencer and its sample time.
  */
  sConfig.Channel = ADC_CHANNEL_3;
  sConfig.Rank = 4;
  if (HAL_ADC_ConfigChannel(&hadc1, &sConfig) != HAL_OK)
  {
    Error_Handler();
  }

  /** Configure for the selected ADC regular channel its corresponding rank in the sequencer and its sample time.
  */
  sConfig.Channel = ADC_CHANNEL_5;
  sConfig.Rank = 5;
  if (HAL_ADC_ConfigChannel(&hadc1, &sConfig) != HAL_OK)
  {
    Error_Handler();
  }

  /** Configure for the selected ADC regular channel its corresponding rank in the sequencer and its sample time.
  */
  sConfig.Channel = ADC_CHANNEL_6;
  sConfig.Rank = 6;
  if (HAL_ADC_ConfigChannel(&hadc1, &sConfig) != HAL_OK)
  {
    Error_Handler();
  }

  /** Configure for the selected ADC regular channel its corresponding rank in the sequencer and its sample time.
  */
  sConfig.Channel = ADC_CHANNEL_7;
  sConfig.Rank = 7;
  if (HAL_ADC_ConfigChannel(&hadc1, &sConfig) != HAL_OK)
  {
    Error_Handler();
  }

  /** Configure for the selected ADC regular channel its corresponding rank in the sequencer and its sample time.
  */
  sConfig.Channel = ADC_CHANNEL_8;
  sConfig.Rank = 8;
  if (HAL_ADC_ConfigChannel(&hadc1, &sConfig) != HAL_OK)
  {
    Error_Handler();
  }

  /** Configure for the selected ADC regular channel its corresponding rank in the sequencer and its sample time.
  */
  sConfig.Channel = ADC_CHANNEL_9;
  sConfig.Rank = 9;
  if (HAL_ADC_ConfigChannel(&hadc1, &sConfig) != HAL_OK)
  {
    Error_Handler();
  }

  /** Configure for the selected ADC regular channel its corresponding rank in the sequencer and its sample time.
  */
  sConfig.Channel = ADC_CHANNEL_10;
  sConfig.Rank = 10;
  if (HAL_ADC_ConfigChannel(&hadc1, &sConfig) != HAL_OK)
  {
    Error_Handler();
  }

  /** Configure for the selected ADC regular channel its corresponding rank in the sequencer and its sample time.
  */
  sConfig.Channel = ADC_CHANNEL_11;
  sConfig.Rank = 11;
  if (HAL_ADC_ConfigChannel(&hadc1, &sConfig) != HAL_OK)
  {
    Error_Handler();
  }

  /** Configure for the selected ADC regular channel its corresponding rank in the sequencer and its sample time.
  */
  sConfig.Channel = ADC_CHANNEL_12;
  sConfig.Rank = 12;
  if (HAL_ADC_ConfigChannel(&hadc1, &sConfig) != HAL_OK)
  {
    Error_Handler();
  }

  /** Configure for the selected ADC regular channel its corresponding rank in the sequencer and its sample time.
  */
  sConfig.Channel = ADC_CHANNEL_13;
  sConfig.Rank = 13;
  if (HAL_ADC_ConfigChannel(&hadc1, &sConfig) != HAL_OK)
  {
    Error_Handler();
  }

  /** Configure for the selected ADC regular channel its corresponding rank in the sequencer and its sample time.
  */
  sConfig.Channel = ADC_CHANNEL_15;
  sConfig.Rank = 14;
  if (HAL_ADC_ConfigChannel(&hadc1, &sConfig) != HAL_OK)
  {
    Error_Handler();
  }

}

static void MX_ADC2_Init(void)
{

  ADC_ChannelConfTypeDef sConfig = {0};

  /** Configure the global features of the ADC (Clock, Resolution, Data Alignment and number of conversion)
  */
  hadc2.Instance = ADC2;
  hadc2.Init.ClockPrescaler = ADC_CLOCK_SYNC_PCLK_DIV4;
  hadc2.Init.Resolution = ADC_RESOLUTION_12B;
  hadc2.Init.ScanConvMode = DISABLE;
  hadc2.Init.ContinuousConvMode = ENABLE;
  hadc2.Init.DiscontinuousConvMode = DISABLE;
  hadc2.Init.ExternalTrigConvEdge = ADC_EXTERNALTRIGCONVEDGE_NONE;
  hadc2.Init.ExternalTrigConv = ADC_SOFTWARE_START;
  hadc2.Init.DataAlign = ADC_DATAALIGN_RIGHT;
  hadc2.Init.NbrOfConversion = 1;
  hadc2.Init.DMAContinuousRequests = ENABLE;
  hadc2.Init.EOCSelection = ADC_EOC_SINGLE_CONV;
  if (HAL_ADC_Init(&hadc2) != HAL_OK)
  {
    Error_Handler();
  }

  /** Configure for the selected ADC regular channel its corresponding rank in the sequencer and its sample time.
  */
  sConfig.Channel = ADC_CHANNEL_14;
  sConfig.Rank = 1;
  sConfig.SamplingTime = ADC_SAMPLETIME_3CYCLES;
  if (HAL_ADC_ConfigChannel(&hadc2, &sConfig) != HAL_OK)
  {
    Error_Handler();
  }

}

static void MX_DAC_Init(void)
{

  DAC_ChannelConfTypeDef sConfig = {0};

  /** DAC Initialization
  */
  hdac.Instance = DAC;
  if (HAL_DAC_Init(&hdac) != HAL_OK)
  {
    Error_Handler();
  }

  /** DAC channel OUT1 config
  */
  sConfig.DAC_Trigger = DAC_TRIGGER_T4_TRGO;
  sConfig.DAC_OutputBuffer = DAC_OUTPUTBUFFER_ENABLE;
  if (HAL_DAC_ConfigChannel(&hdac, &sConfig, DAC_CHANNEL_1) != HAL_OK)
  {
    Error_Handler();
  }

}

static void MX_I2C1_Init(void)
{

  hi2c1.Instance = I2C1;
  hi2c1.Init.ClockSpeed = 400000;
  hi2c1.Init.DutyCycle = I2C_DUTYCYCLE_2;
  hi2c1.Init.OwnAddress1 = 0;
  hi2c1.Init.AddressingMode = I2C_ADDRESSINGMODE_7BIT;
  hi2c1.Init.DualAddressMode = I2C_DUALADDRESS_DISABLE;
  hi2c1.Init.OwnAddress2 = 0;
  hi2c1.Init.GeneralCallMode = I2C_GENERALCALL_DISABLE;
  hi2c1.Init.NoStretchMode = I2C_NOSTRETCH_DISABLE;
  if (HAL_I2C_Init(&hi2c1) != HAL_OK)
  {
    Error_Handler();
  }

}

static void MX_RTC_Init(void)
{

  RTC_TimeTypeDef sTime = {0};
  RTC_DateTypeDef sDate = {0};

  /** Initialize RTC Only
  */
  hrtc.Instance = RTC;
  hrtc.Init.HourFormat = RTC_HOURFORMAT_24;
  hrtc.Init.AsynchPrediv = 127;
  hrtc.Init.SynchPrediv = 255;
  hrtc.Init.OutPut = RTC_OUTPUT_DISABLE;
  hrtc.Init.OutPutPolarity = RTC_OUTPUT_POLARITY_HIGH;
  hrtc.Init.OutPutType = RTC_OUTPUT_TYPE_OPENDRAIN;
  if (HAL_RTC_Init(&hrtc) != HAL_OK)
  {
    Error_Handler();
  }

  /** Initialize RTC and set the Time and Date
  */
  sTime.Hours = 0x12;
  sTime.Minutes = 0x40;
  sTime.Seconds = 0x0;
  sTime.DayLightSaving = RTC_DAYLIGHTSAVING_NONE;
  sTime.StoreOperation = RTC_STOREOPERATION_RESET;
  if (HAL_RTC_SetTime(&hrtc, &sTime, RTC_FORMAT_BCD) != HAL_OK)
  {
    Error_Handler();
  }
  sDate.WeekDay = RTC_WEEKDAY_SUNDAY;
  sDate.Month = RTC_MONTH_APRIL;
  sDate.Date = 0x5;
  sDate.Year = 0x25;

  if (HAL_RTC_SetDate(&hrtc, &sDate, RTC_FORMAT_BCD) != HAL_OK)
  {
    Error_Handler();
  }

}

static void MX_SDIO_SD_Init(void)
{

  hsd.Instance = SDIO;
  hsd.Init.ClockEdge = SDIO_CLOCK_EDGE_RISING;
  hsd.Init.ClockBypass = SDIO_CLOCK_BYPASS_DISABLE;
  hsd.Init.ClockPowerSave = SDIO_CLOCK_POWER_SAVE_DISABLE;
  hsd.Init.BusWide = SDIO_BUS_WIDE_1B;
  hsd.Init.HardwareFlowControl = SDIO_HARDWARE_FLOW_CONTROL_DISABLE;
  hsd.Init.ClockDiv = 12;

}

static void MX_TIM4_Init(void)
{

  TIM_ClockConfigTypeDef sClockSourceConfig = {0};
  TIM_MasterConfigTypeDef sMasterConfig = {0};

  htim4.Instance = TIM4;
  htim4.Init.Prescaler = 1679;
  htim4.Init.CounterMode = TIM_COUNTERMODE_UP;
  htim4.Init.Period = 4;
  htim4.Init.ClockDivision = TIM_CLOCKDIVISION_DIV1;
  htim4.Init.AutoReloadPreload = TIM_AUTORELOAD_PRELOAD_DISABLE;
  if (HAL_TIM_Base_Init(&htim4) != HAL_OK)
  {
    Error_Handler();
  }
  sClockSourceConfig.ClockSource = TIM_CLOCKSOURCE_INTERNAL;
  if (HAL_TIM_ConfigClockSource(&htim4, &sClockSourceConfig) != HAL_OK)
  {
    Error_Handler();
  }
  sMasterConfig.MasterOutputTrigger = TIM_TRGO_UPDATE;
  sMasterConfig.MasterSlaveMode = TIM_MASTERSLAVEMODE_DISABLE;
  if (HAL_TIMEx_MasterConfigSynchronization(&htim4, &sMasterConfig) != HAL_OK)
  {
    Error_Handler();
  }

}

static void MX_USART6_UART_Init(void)
{

  huart6.Instance = USART6;
  huart6.Init.BaudRate = 115200;
  huart6.Init.WordLength = UART_WORDLENGTH_8B;
  huart6.Init.StopBits = UART_STOPBITS_1;
  huart6.Init.Parity = UART_PARITY_NONE;
  huart6.Init.Mode = UART_MODE_TX_RX;
  huart6.Init.HwFlowCtl = UART_HWCONTROL_NONE;
  huart6.Init.OverSampling = UART_OVERSAMPLING_16;
  if (HAL_UART_Init(&huart6) != HAL_OK)
  {
    Error_Handler();
  }

}

static void MX_DMA_Init(void)
{

  /* DMA controller clock enable */
  __HAL_RCC_DMA2_CLK_ENABLE();
  __HAL_RCC_DMA1_CLK_ENABLE();

  /* Configure DMA request hdma_memtomem_dma2_stream1 on DMA2_Stream1 */
  hdma_memtomem_dma2_stream1.Instance = DMA2_Stream1;
  hdma_memtomem_dma2_stream1.Init.Channel = DMA_CHANNEL_0;
  hdma_memtomem_dma2_stream1.Init.Direction = DMA_MEMORY_TO_MEMORY;
  hdma_memtomem_dma2_stream1.Init.PeriphInc = DMA_PINC_ENABLE;
  hdma_memtomem_dma2_stream1.Init.MemInc = DMA_MINC_ENABLE;
  hdma_memtomem_dma2_stream1.Init.PeriphDataAlignment = DMA_PDATAALIGN_HALFWORD;
  hdma_memtomem_dma2_stream1.Init.MemDataAlignment = DMA_MDATAALIGN_HALFWORD;
  hdma_memtomem_dma2_stream1.Init.Mode = DMA_NORMAL;
  hdma_memtomem_dma2_stream1.Init.Priority = DMA_PRIORITY_HIGH;
  hdma_memtomem_dma2_stream1.Init.FIFOMode = DMA_FIFOMODE_ENABLE;
  hdma_memtomem_dma2_stream1.Init.FIFOThreshold = DMA_FIFO_THRESHOLD_FULL;
  hdma_memtomem_dma2_stream1.Init.MemBurst = DMA_MBURST_SINGLE;
  hdma_memtomem_dma2_stream1.Init.PeriphBurst = DMA_PBURST_SINGLE;
  if (HAL_DMA_Init(&hdma_memtomem_dma2_stream1) != HAL_OK)
  {
    Error_Handler( );
  }

  /* DMA interrupt init */
  /* DMA1_Stream5_IRQn interrupt configuration */
  HAL_NVIC_SetPriority(DMA1_Stream5_IRQn, 0, 0);
  HAL_NVIC_EnableIRQ(DMA1_Stream5_IRQn);
  /* DMA2_Stream2_IRQn interrupt configuration */
  HAL_NVIC_SetPriority(DMA2_Stream2_IRQn, 0, 0);
  HAL_NVIC_EnableIRQ(DMA2_Stream2_IRQn);
  /* DMA2_Stream3_IRQn interrupt configuration */
  HAL_NVIC_SetPriority(DMA2_Stream3_IRQn, 0, 0);
  HAL_NVIC_EnableIRQ(DMA2_Stream3_IRQn);
  /* DMA2_Stream4_IRQn interrupt configuration */
  HAL_NVIC_SetPriority(DMA2_Stream4_IRQn, 0, 0);
  HAL_NVIC_EnableIRQ(DMA2_Stream4_IRQn);
  /* DMA2_Stream6_IRQn interrupt configuration */
  HAL_NVIC_SetPriority(DMA2_Stream6_IRQn, 0, 0);
  HAL_NVIC_EnableIRQ(DMA2_Stream6_IRQn);

}

static void MX_GPIO_Init(void)
{
  GPIO_InitTypeDef GPIO_InitStruct = {0};

  /* GPIO Ports Clock Enable */
  __HAL_RCC_GPIOF_CLK_ENABLE();
  __HAL_RCC_GPIOH_CLK_ENABLE();
  __HAL_RCC_GPIOC_CLK_ENABLE();
  __HAL_RCC_GPIOA_CLK_ENABLE();
  __HAL_RCC_GPIOB_CLK_ENABLE();
  __HAL_RCC_GPIOG_CLK_ENABLE();
  __HAL_RCC_GPIOE_CLK_ENABLE();
  __HAL_RCC_GPIOD_CLK_ENABLE();

  /*Configure GPIO pin Output Level */
  HAL_GPIO_WritePin(GPIOF, GPIO_PIN_9, GPIO_PIN_RESET);

  /*Configure GPIO pin Output Level */
  HAL_GPIO_WritePin(GPIOB, GPIO_PIN_15, GPIO_PIN_RESET);

  /*Configure GPIO pin : PF9 */
  GPIO_InitStruct.Pin = GPIO_PIN_9;
  GPIO_InitStruct.Mode = GPIO_MODE_OUTPUT_PP;
  GPIO_InitStruct.Pull = GPIO_NOPULL;
  GPIO_InitStruct.Speed = GPIO_SPEED_FREQ_LOW;
  HAL_GPIO_Init(GPIOF, &GPIO_InitStruct);

  /*Configure GPIO pins : PB10 PB11 */
  GPIO_InitStruct.Pin = GPIO_PIN_10|GPIO_PIN_11;
  GPIO_InitStruct.Mode = GPIO_MODE_INPUT;
  GPIO_InitStruct.Pull = GPIO_PULLDOWN;
  HAL_GPIO_Init(GPIOB, &GPIO_InitStruct);

  /*Configure GPIO pin : PB12 */
  GPIO_InitStruct.Pin = GPIO_PIN_12;
  GPIO_InitStruct.Mode = GPIO_MODE_INPUT;
  GPIO_InitStruct.Pull = GPIO_NOPULL;
  HAL_GPIO_Init(GPIOB, &GPIO_InitStruct);

  /*Configure GPIO pin : PB15 */
  GPIO_InitStruct.Pin = GPIO_PIN_15;
  GPIO_InitStruct.Mode = GPIO_MODE_OUTPUT_PP;
  GPIO_InitStruct.Pull = GPIO_NOPULL;
  GPIO_InitStruct.Speed = GPIO_SPEED_FREQ_LOW;
  HAL_GPIO_Init(GPIOB, &GPIO_InitStruct);

}

/* FSMC initialization function */
static void MX_FSMC_Init(void)
{

  FSMC_NORSRAM_TimingTypeDef Timing = {0};

  /** Perform the SRAM1 memory initialization sequence
  */
  hsram1.Instance = FSMC_NORSRAM_DEVICE;
  hsram1.Extended = FSMC_NORSRAM_EXTENDED_DEVICE;
  /* hsram1.Init */
  hsram1.Init.NSBank = FSMC_NORSRAM_BANK4;
  hsram1.Init.DataAddressMux = FSMC_DATA_ADDRESS_MUX_DISABLE;
  hsram1.Init.MemoryType = FSMC_MEMORY_TYPE_SRAM;
  hsram1.Init.MemoryDataWidth = FSMC_NORSRAM_MEM_BUS_WIDTH_16;
  hsram1.Init.BurstAccessMode = FSMC_BURST_ACCESS_MODE_DISABLE;
  hsram1.Init.WaitSignalPolarity = FSMC_WAIT_SIGNAL_POLARITY_LOW;
  hsram1.Init.WrapMode = FSMC_WRAP_MODE_DISABLE;
  hsram1.Init.WaitSignalActive = FSMC_WAIT_TIMING_BEFORE_WS;
  hsram1.Init.WriteOperation = FSMC_WRITE_OPERATION_ENABLE;
  hsram1.Init.WaitSignal = FSMC_WAIT_SIGNAL_DISABLE;
  hsram1.Init.ExtendedMode = FSMC_EXTENDED_MODE_DISABLE;
  hsram1.Init.AsynchronousWait = FSMC_ASYNCHRONOUS_WAIT_DISABLE;
  hsram1.Init.WriteBurst = FSMC_WRITE_BURST_DISABLE;
  hsram1.Init.PageSize = FSMC_PAGE_SIZE_NONE;
  /* Timing */
  Timing.AddressSetupTime = 1;
  Timing.AddressHoldTime = 15;
  Timing.DataSetupTime = 5;
  Timing.BusTurnAroundDuration = 0;
  Timing.CLKDivision = 16;
  Timing.DataLatency = 17;
  Timing.AccessMode = FSMC_ACCESS_MODE_A;
  /* ExtTiming */

  if (HAL_SRAM_Init(&hsram1, &Timing, NULL) != HAL_OK)
  {
    Error_Handler( );
  }

  /** Perform the SRAM2 memory initialization sequence
  */
  hsram2.Instance = FSMC_NORSRAM_DEVICE;
  hsram2.Extended = FSMC_NORSRAM_EXTENDED_DEVICE;
  /* hsram2.Init */
  hsram2.Init.NSBank = FSMC_NORSRAM_BANK3;
  hsram2.Init.DataAddressMux = FSMC_DATA_ADDRESS_MUX_DISABLE;
  hsram2.Init.MemoryType = FSMC_MEMORY_TYPE_SRAM;
  hsram2.Init.MemoryDataWidth = FSMC_NORSRAM_MEM_BUS_WIDTH_16;
  hsram2.Init.BurstAccessMode = FSMC_BURST_ACCESS_MODE_DISABLE;
  hsram2.Init.WaitSignalPolarity = FSMC_WAIT_SIGNAL_POLARITY_LOW;
  hsram2.Init.WrapMode = FSMC_WRAP_MODE_DISABLE;
  hsram2.Init.WaitSignalActive = FSMC_WAIT_TIMING_BEFORE_WS;
  hsram2.Init.WriteOperation = FSMC_WRITE_OPERATION_ENABLE;
  hsram2.Init.WaitSignal = FSMC_WAIT_SIGNAL_DISABLE;
  hsram2.Init.ExtendedMode = FSMC_EXTENDED_MODE_DISABLE;
  hsram2.Init.AsynchronousWait = FSMC_ASYNCHRONOUS_WAIT_DISABLE;
  hsram2.Init.WriteBurst = FSMC_WRITE_BURST_DISABLE;
  hsram2.Init.PageSize = FSMC_PAGE_SIZE_NONE;
  /* Timing */
  Timing.AddressSetupTime = 0;
  Timing.AddressHoldTime = 15;
  Timing.DataSetupTime = 8;
  Timing.BusTurnAroundDuration = 0;
  Timing.CLKDivision = 16;
  Timing.DataLatency = 17;
  Timing.AccessMode = FSMC_ACCESS_MODE_A;
  /* ExtTiming */

  if (HAL_SRAM_Init(&hsram2, &Timing, NULL) != HAL_OK)
  {
    Error_Handler( );
  }

}

void Error_Handler(void)
{
  __disable_irq();
  while (1)
  {
  }
}
